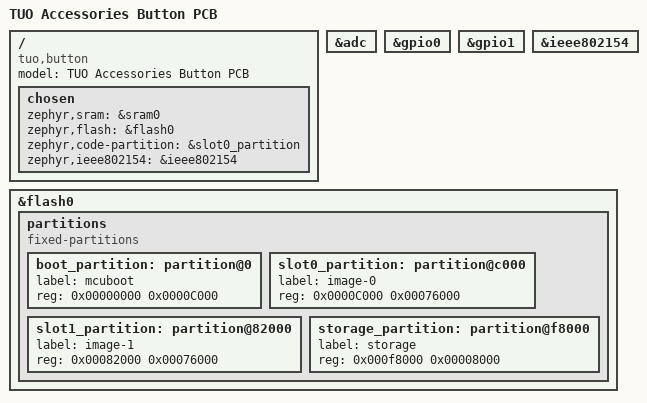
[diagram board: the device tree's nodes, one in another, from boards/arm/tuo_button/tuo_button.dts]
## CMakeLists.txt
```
cmake_minimum_required(VERSION 3.20.0)

find_package(Zephyr HINTS $ENV{ZEPHYR_BASE})

project(button)

include($ENV{MATTER_BASE}/config/nrfconnect/app/enable-gnu-std.cmake)
include($ENV{MATTER_BASE}/src/app/chip_data_model.cmake)

target_include_directories(app PRIVATE include matter)

target_sources(app PRIVATE
    src/main.cpp
    src/app_task.cpp
    src/button.cpp
    src/reset_switch.cpp
    src/battery.cpp
    matter/zap-generated/IMClusterCommandHandler.cpp
    matter/zap-generated/callback-stub.cpp
)

chip_configure_data_model(app
    INCLUDE_SERVER
    ZAP_FILE ${CMAKE_CURRENT_SOURCE_DIR}/matter/button.zap
)
```

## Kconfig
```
mainmenu "Button"

config BUTTON_GPIO
	int "Button GPIO"
	default 6

config RESET_SWITCH_GPIO
	int "Reset switch GPIO"
	default 24

source "${ZEPHYR_BASE}/../modules/lib/matter/config/nrfconnect/chip-module/Kconfig.features"
source "${ZEPHYR_BASE}/../modules/lib/matter/config/nrfconnect/chip-module/Kconfig.defaults"
source "Kconfig.zephyr"
```

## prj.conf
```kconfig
#
# Copyright (c) 2022 Nordic Semiconductor ASA
#
# SPDX-License-Identifier: LicenseRef-Nordic-5-Clause
#

# Version
CONFIG_CHIP_DEVICE_SOFTWARE_VERSION=1
CONFIG_CHIP_DEVICE_SOFTWARE_VERSION_STRING="0.1.0"

# CHIP
CONFIG_CHIP=y
CONFIG_CHIP_PROJECT_CONFIG="matter/chip_project_config.h"
CONFIG_CHIP_ENABLE_SLEEPY_END_DEVICE_SUPPORT=y
CONFIG_CHIP_THREAD_SSED=y
CONFIG_CHIP_ENABLE_PAIRING_AUTOSTART=y
CONFIG_CHIP_DEVICE_TYPE=15

# Thread
CONFIG_OPENTHREAD_MTD=y
CONFIG_OPENTHREAD_NORDIC_LIBRARY_MTD=y
CONFIG_OPENTHREAD_NRF_SECURITY_CHOICE=y

# Bluetooth
CONFIG_BT_DEVICE_NAME="Button"

# MCUboot
CONFIG_BOOTLOADER_MCUBOOT=n

# Other settings
CONFIG_STD_CPP14=y
CONFIG_THREAD_NAME=y
CONFIG_MPU_STACK_GUARD=y
CONFIG_RESET_ON_FATAL_ERROR=n
CONFIG_NET_IF_MCAST_IPV6_ADDR_COUNT=14
CONFIG_ADC=y

# RTT logging
CONFIG_STDOUT_CONSOLE=y
CONFIG_UART_CONSOLE=n
CONFIG_USE_SEGGER_RTT=y
CONFIG_SHELL_BACKEND_RTT=y
CONFIG_LOG_DEFAULT_LEVEL=4

#CONFIG_BUTTON_SINGLE_PRESS_TIME=100
#CONFIG_BUTTON_DOUBLE_PRESS_TIME=250
#CONFIG_BUTTON_LONG_PRESS_TIME=1000
```

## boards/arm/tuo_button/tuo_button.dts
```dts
/dts-v1/;
#include <nordic/nrf52840_qiaa.dtsi>

/ {
  model = "TUO Accessories Button PCB";
  compatible = "tuo,button";

  chosen {
    zephyr,sram = &sram0;
    zephyr,flash = &flash0;
    zephyr,code-partition = &slot0_partition;
    zephyr,ieee802154 = &ieee802154;
  };
};

&adc {
  status = "okay";
};

&gpio0 {
  status = "okay";
};

&gpio1 {
  status = "okay";
};

&ieee802154 {
  status = "okay";
};

&flash0 {
    partitions {
        compatible = "fixed-partitions";
        #address-cells = <1>;
        #size-cells = <1>;

        boot_partition: partition@0 {
          label = "mcuboot";
          reg = <0x00000000 0x0000C000>;
        };
        slot0_partition: partition@c000 {
          label = "image-0";
          reg = <0x0000C000 0x00076000>;
        };
        slot1_partition: partition@82000 {
          label = "image-1";
          reg = <0x00082000 0x00076000>;
        };
        storage_partition: partition@f8000 {
          label = "storage";
          reg = <0x000f8000 0x00008000>;
        };
    };
};
```

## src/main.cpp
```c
#include <zephyr/logging/log.h>
#include "app_task.hpp"

LOG_MODULE_REGISTER(app);

int main() {
	auto& task = AppTask::shared();

    auto err = task.init();

    if (err != 0) {
        LOG_ERR("Failed to initialize. Exiting...");
        return EXIT_FAILURE;
    }

    err = task.start();

    return err == 0 ? EXIT_SUCCESS : EXIT_FAILURE;
}
```

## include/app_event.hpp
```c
#pragma once

struct AppEvent;

typedef void (*event_callback_fn)(AppEvent event);

enum class AppEventType: unsigned char {
    None = 0,
    ButtonChanged
};

struct AppEvent {
    AppEventType type;
    event_callback_fn callback;

    union {
        struct {
            // Status returned from GPIO read
            // 0 = pressed, 1 = released, other values are errors
            int status;
        } button_changed;
    };
};
```

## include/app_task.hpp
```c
/*
 * Copyright (c) 2021 Nordic Semiconductor ASA
 *
 * SPDX-License-Identifier: LicenseRef-Nordic-5-Clause
 */

#pragma once

#include <platform/CHIPDeviceLayer.h>
#include "app_event.hpp"

class AppTask {
public:
	static AppTask& shared() {
		static AppTask app_task;
		return app_task;
	};

    bool initialized() const;
    int init();

    int start();

private:
    static void on_chip_event(const chip::DeviceLayer::ChipDeviceEvent* event, intptr_t arg);
    static void on_button_interrupt(int status);
    static void on_reset();

    static void on_button_change(AppEvent event);

    static void set_button(bool pressed);

    bool _initialized = false;
};
```

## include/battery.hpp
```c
#pragma once

namespace battery {

    // Initializes the battery management system
    int init();

    // Gets the current battery percentage
    // Positive values indicate half battery percentages (200 = 100%, 100 = 50%, etc..), negative values an error
    int get_percentage();

}
```

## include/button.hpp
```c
#pragma once

#include "zephyr/drivers/gpio.h"

typedef void (*button_interrupt_fn)(int status);

namespace button {
    // Initializes the button
    int init();

    // Read a value from the button
    // Returns an integer indicating the status of the GPIO read
    // 0 = pressed, 1 = released, other values are errors
    int read();

    // Enables the button interrupt with the specified callback
    // Can only be run once
    int enable_interrupt(button_interrupt_fn interrupt_handler);
}
```

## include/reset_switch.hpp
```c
#pragma once

#include "zephyr/drivers/gpio.h"

typedef void (*reset_fn)();

namespace reset_switch {
    // Initializes the reset switch
    int init();

    // Read a value from the reset switch
    // Returns an integer indicating the status of the GPIO read
    // 0 = pressed, 1 = not pressed, other values are errors
    int read();

    // Enables the reset switch interrupt with the specified callback
    // Can only be run once
    int enable_interrupt(reset_fn reset_handler);
}
```

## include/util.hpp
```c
#pragma once

#define CHECK_STATUS(info, status, condition) if ((status) condition) { LOG_ERR("Invalid status while " info ": %d", status); return status; }
#define CHECK_SUCCESS(info, status) CHECK_STATUS(info, status, != 0)

#define CHECK_STATUS_VOID(info, status, condition) if ((status) condition) { LOG_ERR("Invalid status while " info ": %d", status); return; }
#define CHECK_SUCCESS_VOID(info, status) CHECK_STATUS_VOID(info, status, != 0)

#define CHECK_CHIP_STATUS(info, status, condition) if ((status) condition) { LOG_ERR("Invalid status while " info ": %s (%d)", status.AsString(), status.AsInteger()); return status.AsInteger(); }
#define CHECK_CHIP_SUCCESS(info, status) CHECK_CHIP_STATUS(info, status, != CHIP_NO_ERROR)
```

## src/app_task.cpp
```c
#include "app_task.hpp"


#include <app/server/OnboardingCodesUtil.h>
#include <app/server/Server.h>
#include <app/clusters/switch-server/switch-server.h>
#include <app-common/zap-generated/attribute-id.h>
#include <app-common/zap-generated/attribute-type.h>
#include <app-common/zap-generated/attributes/Accessors.h>
#include <app-common/zap-generated/cluster-id.h>
#include <platform/CHIPDeviceLayer.h>
#include <platform/ThreadStackManager.h>
#include <credentials/DeviceAttestationCredsProvider.h>
#include <credentials/examples/DeviceAttestationCredsExample.h>

#include "app_event.hpp"
#include "button.hpp"
#include "reset_switch.hpp"
#include "battery.hpp"
#include "util.hpp"

LOG_MODULE_DECLARE(app);

using namespace ::chip::Credentials;
using namespace ::chip::DeviceLayer;

constexpr chip::EndpointId button_endpoint = 1;

K_MSGQ_DEFINE(app_event_queue, sizeof(AppEvent), 10, alignof(AppEvent));

int AppTask::init() {
    LOG_INF("Initializing...");

    // Hardware initialization
    int err = button::init();
    CHECK_SUCCESS("initializing button", err)

    err = reset_switch::init();
    CHECK_SUCCESS("initializing reset switch", err)

    err = battery::init();
    CHECK_SUCCESS("initializing battery management", err)

    // Matter initialization
    CHIP_ERROR chip_err = chip::Platform::MemoryInit();
    CHECK_CHIP_SUCCESS("initializing memory", chip_err)

    chip_err = PlatformMgr().InitChipStack();
    CHECK_CHIP_SUCCESS("initializing Matter stack", chip_err)

    chip_err = ThreadStackMgr().InitThreadStack();
    CHECK_CHIP_SUCCESS("initializing Thread stack", chip_err)

    chip_err = ConnectivityMgr().SetThreadDeviceType(ConnectivityManager::kThreadDeviceType_SynchronizedSleepyEndDevice);
    CHECK_CHIP_SUCCESS("setting Thread device type", chip_err)

    // TODO: Proper credentials
    SetDeviceAttestationCredentialsProvider(Examples::GetExampleDACProvider());

    // TODO: Proper parameter storage
    static chip::CommonCaseDeviceServerInitParams init_params;
    init_params.InitializeStaticResourcesBeforeServerInit();

    chip_err = chip::Server::GetInstance().Init(init_params);
    CHECK_CHIP_SUCCESS("initializing server", chip_err)

    ConfigurationMgr().LogDeviceConfig();
    PrintOnboardingCodes(chip::RendezvousInformationFlag::kBLE);

    chip_err = PlatformMgr().AddEventHandler(on_chip_event, 0);
    CHECK_CHIP_SUCCESS("adding CHIP event handler", chip_err)

    chip_err = PlatformMgr().StartEventLoopTask();
    CHECK_CHIP_SUCCESS("starting event loop task", chip_err)

    _initialized = true;
    return 0;
}

int AppTask::start() {
    if (!_initialized) {
        LOG_ERR("Application is not initialized");
        return 1;
    }

    int status = button::enable_interrupt(on_button_interrupt);
    CHECK_SUCCESS("enabling button interrupt", status)

    status = button::read();

    if (status != 0 && status != 1) {
        LOG_ERR("Invalid button status on initial read: %i", status);
    } else {
        set_button(status == 0);
    }

    status = reset_switch::enable_interrupt(on_reset);
    CHECK_SUCCESS("enabling reset switch interrupt", status)

    auto percentage = battery::get_percentage();
    CHECK_STATUS("getting battery percentage", percentage, < 0);
    LOG_INF("Current battery percentage: %d%%", percentage / 2);

    AppEvent event {};

    while (true) {
        status = k_msgq_get(&app_event_queue, &event, K_FOREVER);

        if (status != 0) {
            LOG_WRN("App event queue returned invalid status: %i", status);
            continue;
        }

        if (event.callback) {
            event.callback(event);
        } else {
            LOG_WRN("App event does not have a callback");
        }
    }
}

void AppTask::on_chip_event(const chip::DeviceLayer::ChipDeviceEvent* event, intptr_t /* arg */) {
    LOG_INF("CHIP event: %u", event->Type);
}

void AppTask::on_button_interrupt(int status) {
    LOG_INF("Button status: %d", status);
    AppEvent event {
        .type = AppEventType::ButtonChanged,
        .callback = on_button_change,
        .button_changed = {
            .status = status
        }
    };

    auto _status = k_msgq_put(&app_event_queue, &event, K_NO_WAIT);

    if (_status != 0) {
        LOG_ERR("Failed to post ButtonChanged event: %i", _status);
    }
}

void AppTask::on_reset() {
    LOG_INF("Performing factory reset");
    chip::Server::GetInstance().ScheduleFactoryReset();
}

void AppTask::on_button_change(AppEvent event) {
    if (event.type != AppEventType::ButtonChanged) return;

    auto status = event.button_changed.status;

    if (status != 0 && status != 1) {
        LOG_ERR("Invalid status in ButtonChanged event: %i", status);
        return;
    }

    set_button(status == 0);
}

void AppTask::set_button(bool pressed) {
    SystemLayer().ScheduleLambda([pressed] {
        auto status = chip::app::Clusters::Switch::Attributes::CurrentPosition::Set(button_endpoint, pressed);

        if (pressed) {
            chip::app::Clusters::SwitchServer::Instance().OnInitialPress(button_endpoint, 1);
        } else {
            chip::app::Clusters::SwitchServer::Instance().OnShortRelease(button_endpoint, 1);
        }

        if (status != EMBER_ZCL_STATUS_SUCCESS) {
            LOG_ERR("Failed to update button cluster: %i", status);
        }
    });
}

bool AppTask::initialized() const { return _initialized; }
```

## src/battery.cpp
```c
#include "battery.hpp"

#include <zephyr/drivers/adc.h>
#include <zephyr/logging/log.h>
#include "util.hpp"

LOG_MODULE_DECLARE(app);

namespace battery {

    namespace {
        const struct device* _device = DEVICE_DT_GET(DT_NODELABEL(adc));

        const struct adc_channel_cfg _adc_config {
            .gain = ADC_GAIN_1_6,
            .reference = ADC_REF_INTERNAL,
            .acquisition_time = ADC_ACQ_TIME(ADC_ACQ_TIME_MICROSECONDS, 40),
            .channel_id = 0,
            .differential = 0,
            .input_positive = SAADC_CH_PSELP_PSELP_VDD
        };
    }

    int init() {
        LOG_DBG("Initializing battery management");

        int status = adc_channel_setup(_device, &_adc_config);

        CHECK_SUCCESS("initializing battery ADC", status)

        return status;
    }

    int get_percentage() {
        int sample = 0;

        struct adc_sequence sequence {
            .channels = BIT(0),
            .buffer = &sample,
            .buffer_size = sizeof(sample),
            .resolution = 14,
            .oversampling = 4,
            .calibrate = true
        };

        int status = adc_read(_device, &sequence);
        CHECK_SUCCESS("measuring battery ADC", status);

        auto ref = adc_ref_internal(_device);

        LOG_DBG("Battery raw: %u, reference: %u", sample, ref);

        adc_raw_to_millivolts(ref, _adc_config.gain, sequence.resolution, &sample);

        LOG_DBG("Battery mV: %d", sample);

        // Clip from 2V to 3V
        sample = sample <= 3000 ? (sample >= 2000 ? sample : 2000) : 3000;

        // Discharge curve for CR2430 shows near linear line to 2.5V for the first 80%, dropping faster to 2V for the last 20%
        // This results in the following equations:
        // Above 2500, percentage = sample * 80/500 - 380
        // Below 2500, percentage = sample * 20/500 - 80

        return sample >= 2500 ? sample * 80 / 500 - 380 : sample * 20/500 - 80;
    }

}
```

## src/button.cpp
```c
#include "button.hpp"

#include <zephyr/drivers/gpio.h>
#include <zephyr/logging/log.h>
#include <zephyr/kernel.h>
#include "util.hpp"


LOG_MODULE_DECLARE(app);

namespace button {

    namespace {
        const struct device* _device = DEVICE_DT_GET(DT_NODELABEL(gpio0));

        struct gpio_callback _callback;
        button_interrupt_fn _interrupt_handler;

        // State machine
        enum button_state_t {
            BUTTON_RELEASED,
            BUTTON_WAIT_DOUBLE_PRESS_OR_LONG_PRESS,
            BUTTON_WAIT_LONG_PRESS
        };

        enum button_event_t{
            BUTTON_SINGLE_PRESSED,
            BUTTON_DOUBLE_PRESSED,
            BUTTON_LONG_PRESSED
        };

        button_state_t _button_state = BUTTON_RELEASED;

         // Timers
        K_TIMER_DEFINE(_double_press_timer, nullptr, nullptr);
        K_TIMER_DEFINE(_long_press_timer, nullptr, nullptr);

        // Timer callback functions
        void double_press_timer_callback(k_timer* timer_id) {
            LOG_INF("Double press timer expired");
            _button_state = BUTTON_RELEASED;
            _interrupt_handler(BUTTON_SINGLE_PRESSED);
        }

        void long_press_timer_callback(k_timer* timer_id) {
            LOG_INF("Long press timer expired");
            _button_state = BUTTON_RELEASED;
            _interrupt_handler(BUTTON_LONG_PRESSED);
        }

        // Timestamp of the last button press
        uint32_t _last_button_press_time = 0;

        // Number of button presses
        int _num_button_presses = 0;

        /*void gpio_handler(const struct device* port, struct gpio_callback* callback, gpio_port_pins_t pins) {
            LOG_INF("*****************************\n");
            LOG_INF("*****************************\n");
            LOG_INF("\n\n");
            
            // This call should not be delayed
            int value = read();
            _interrupt_handler(value);
        }

        void gpio_handler(const struct device* port, struct gpio_callback* callback, gpio_port_pins_t pins) {
            int value = read();
            uint32_t current_time = k_uptime_get_32();

            if (value == 0) {
                // Button is pressed
                if (_button_state == BUTTON_RELEASED) {
                    // Button was just pressed
                    _button_state = BUTTON_PRESSED;
                    _last_button_press_time = current_time;
                    //LOG_INF("Button pressed");
                } else if (_button_state == BUTTON_PRESSED) {
                    // Button was already pressed
                    if (current_time - _last_button_press_time >= 1000) {
                        // Button has been held down for more than 1 second, trigger long press
                        _button_state = BUTTON_LONG_PRESSED;
                        _interrupt_handler(BUTTON_LONG_PRESSED);
                        LOG_INF("Button long press");
                    }
                } else if (_button_state == BUTTON_LONG_PRESSED) {
                    // Button was already long pressed
                    // Do nothing
                } else if (_button_state == BUTTON_DOUBLE_PRESSED) {
                    // Button was already double pressed
                    // Do nothing
                }
            } else {
                // Button is released
                if (_button_state == BUTTON_PRESSED) {
                    // Button was just released
                    if (current_time - _last_button_press_time >= 250) {
                        // Button was released after less than 250ms, trigger double press
                        _num_button_presses += 1;
                        if (_num_button_presses == 2) {
                            _button_state = BUTTON_DOUBLE_PRESSED;
                            _interrupt_handler(BUTTON_DOUBLE_PRESSED);
                            _num_button_presses = 0;
                            LOG_INF("Button double press");
                        } else {
                            // Wait for another button press
                            _last_button_press_time = current_time;
                        }
                    } else {
                        // Button was released after more than 250ms, trigger single press
                        _button_state = BUTTON_RELEASED;
                        _interrupt_handler(BUTTON_RELEASED);
                        LOG_INF("Button single press");
                    }
                } else if (_button_state == BUTTON_LONG_PRESSED) {
                    // Button was just released after a long press
                    _button_state = BUTTON_RELEASED;
                    _interrupt_handler(BUTTON_RELEASED);
                    //LOG_INF("Button long press released");
                } else if (_button_state == BUTTON_DOUBLE_PRESSED) {
                    // Button was just released after a double press
                    _button_state = BUTTON_RELEASED;
                    _interrupt_handler(BUTTON_RELEASED);
                    //LOG_INF("Button double press released");
                }
            }
        }*/
/*
        // GPIO interrupt handler
        void gpio_handler(const struct device* port, struct gpio_callback* callback, gpio_port_pins_t pins) {
            if (pins & BIT(CONFIG_BUTTON_GPIO)) {
                int value = read();
                switch (_button_state) {
                    case BUTTON_RELEASED:
                        if (value == 0) {
                            _button_state = BUTTON_WAIT_PRESS;
                            k_timer_start(&_single_press_timer, K_MSEC(CONFIG_BUTTON_SINGLE_PRESS_TIME), K_NO_WAIT);
                            LOG_INF("Button pressed, waiting for release or double press");
                        }
                        break;
                    case BUTTON_WAIT_PRESS:
                        if (value == 1) {
                            k_timer_stop(&_single_press_timer);
                            _button_state = BUTTON_RELEASED;
                            _interrupt_handler(BUTTON_SINGLE_PRESSED);
                            LOG_INF("Button single pressed");
                        } else if (k_timer_status_get(&_single_press_timer) > 0) {
                            _button_state = BUTTON_WAIT_DOUBLE_PRESS;
                            k_timer_start(&_double_press_timer, K_MSEC(CONFIG_BUTTON_DOUBLE_PRESS_TIME), K_NO_WAIT);
                            LOG_INF("Button pressed again, waiting for release or triple press");
                        }
                        break;
                    case BUTTON_WAIT_DOUBLE_PRESS:
                        if (value == 1) {
                            k_timer_stop(&_double_press_timer);
                            _button_state = BUTTON_RELEASED;
                            _interrupt_handler(BUTTON_DOUBLE_PRESSED);
                            LOG_INF("Button double pressed");
                        } else if (k_timer_status_get(&_double_press_timer) > 0) {
                            _button_state = BUTTON_WAIT_LONG_PRESS;
                            k_timer_start(&_long_press_timer, K_MSEC(CONFIG_BUTTON_LONG_PRESS_TIME), K_NO_WAIT);
                            LOG_INF("Button pressed again, waiting for long press");
                        }
                        break;
                    case BUTTON_WAIT_LONG_PRESS:
                        if (value == 1) {
                            k_timer_stop(&_long_press_timer);
                            _button_state = BUTTON_RELEASED;
                            _interrupt_handler(BUTTON_LONG_PRESSED);
                            LOG_INF("Button long pressed");
                        }
                        break;
                }
            }
        }
*/

         // GPIO interrupt handler
        void gpio_handler(const struct device* port, struct gpio_callback* callback, gpio_port_pins_t pins) {
            int value = read();
            if (value == 0) {
                if (_button_state == BUTTON_RELEASED) {
                    _button_state = BUTTON_WAIT_DOUBLE_PRESS_OR_LONG_PRESS;
                    //k_timer_start(&_double_press_timer, K_MSEC(CONFIG_BUTTON_DOUBLE_PRESS_TIME), K_NO_WAIT);
                    k_timer_start(&_double_press_timer, K_MSEC(250), K_NO_WAIT);
                    LOG_INF("*********Button pressed, waiting for double press or long press");
                } else if (_button_state == BUTTON_WAIT_DOUBLE_PRESS_OR_LONG_PRESS) {
                    _button_state = BUTTON_WAIT_LONG_PRESS;
                    k_timer_stop(&_double_press_timer);
                    //k_timer_start(&_long_press_timer, K_MSEC(CONFIG_BUTTON_LONG_PRESS_TIME), K_NO_WAIT);
                    k_timer_start(&_long_press_timer, K_MSEC(1000), K_NO_WAIT);
                    LOG_INF("*********Button pressed twice, waiting for long press");
                }
            } else {
                if (_button_state == BUTTON_WAIT_LONG_PRESS) {
                    k_timer_stop(&_long_press_timer);
                    _button_state = BUTTON_RELEASED;
                    _interrupt_handler(BUTTON_LONG_PRESSED);
                    LOG_INF("*********Button long pressed");
                } else if (_button_state == BUTTON_WAIT_DOUBLE_PRESS_OR_LONG_PRESS) {
                    k_timer_stop(&_double_press_timer);
                    _button_state = BUTTON_RELEASED;
                    _interrupt_handler(BUTTON_SINGLE_PRESSED);
                    LOG_INF("*********Button single pressed");
                }
            }
        }






    }

    int init() {
        //LOG_DBG("Initializing button GPIO: %i", CONFIG_BUTTON_GPIO);
        LOG_INF("Initializing button GPIO: %i", CONFIG_BUTTON_GPIO);

        int status = gpio_pin_configure(_device, CONFIG_BUTTON_GPIO, GPIO_INPUT);// | GPIO_PULL_UP);

        CHECK_SUCCESS("initializing button GPIO", status)

        return status;
    }

    int read() {
        //LOG_DBG("Reading button GPIO: %i", CONFIG_BUTTON_GPIO);
        //LOG_INF("Reading button GPIO: %i", CONFIG_BUTTON_GPIO);

        int status = gpio_pin_get(_device, CONFIG_BUTTON_GPIO);

        //CHECK_STATUS("reading button GPIO", status, < 0)

        return status;
    }

    int enable_interrupt(button_interrupt_fn interrupt_handler) {
        //LOG_DBG("Enabling button interrupt");
        LOG_INF("Enabling button interrupt");

        if (!interrupt_handler) {
            LOG_ERR("Invalid parameter for button enable interrupt: interrupt_handler is null");
            return 1;
        }

        if (_interrupt_handler) {
            LOG_ERR("Button interrupt already configured");
            return 1;
        }

        _interrupt_handler = interrupt_handler;

        int status = gpio_pin_interrupt_configure(_device, CONFIG_BUTTON_GPIO, GPIO_INT_EDGE_BOTH);

        CHECK_SUCCESS("configuring button GPIO interrupt", status)

        gpio_init_callback(&_callback, gpio_handler, BIT(CONFIG_BUTTON_GPIO));
        status = gpio_add_callback(_device, &_callback);

        CHECK_SUCCESS("adding button GPIO callback", status)

         // Start the timers
        k_timer_init(&_double_press_timer, double_press_timer_callback, nullptr);
        k_timer_init(&_long_press_timer, long_press_timer_callback, nullptr);

        return status;
    }
}
```

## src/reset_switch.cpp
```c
#include "reset_switch.hpp"

#include <zephyr/drivers/gpio.h>
#include <zephyr/logging/log.h>
#include <zephyr/kernel.h>
#include "util.hpp"

LOG_MODULE_DECLARE(app);

namespace reset_switch {

    namespace {
        const struct device* _device = DEVICE_DT_GET(DT_NODELABEL(gpio0));

        struct gpio_callback _callback;
        reset_fn _reset_handler;

        // Timer work handler
        // Called from the system work queue, calling the reset handler
        void work_handler(struct k_work* work) {
            _reset_handler();
        }

        K_WORK_DEFINE(_work, work_handler);

        // Timer handler for reset switch
        // Dispatches a work item to the system work queue, so the reset handler is not running in the ISR
        void timer_handler(struct k_timer* timer) {
            k_work_submit(&_work);
            k_timer_stop(timer);
        }

        K_TIMER_DEFINE(_timer, timer_handler, nullptr);

        // Interrupt handler for reset switch
        // When the switch is pressed, it starts the timer for 5 seconds
        // When the switch is released, it stops the timer
        void gpio_handler(const struct device* port, struct gpio_callback* callback, gpio_port_pins_t pins) {
            // This call should not be delayed
            int value = read();

            if (value == 0) {
                k_timer_start(&_timer, K_SECONDS(5), K_FOREVER);
            } else if (value == 1) {
                k_timer_stop(&_timer);
            }
        }

    }

    int init() {
        LOG_DBG("Initializing reset switch GPIO: %i", CONFIG_RESET_SWITCH_GPIO);

        int status = gpio_pin_configure(_device, CONFIG_RESET_SWITCH_GPIO, GPIO_INPUT);

        CHECK_SUCCESS("initializing reset switch GPIO", status)

        return status;
    }

    int read() {
        LOG_DBG("Reading reset switch GPIO: %i", CONFIG_RESET_SWITCH_GPIO);

        int status = gpio_pin_get(_device, CONFIG_RESET_SWITCH_GPIO);

        CHECK_STATUS("reading reset switch GPIO", status, < 0)

        return status;
    }

    int enable_interrupt(reset_fn reset_handler) {
        LOG_DBG("Enabling reset switch interrupt");

        if (!reset_handler) {
            LOG_ERR("Invalid parameter for reset switch enable interrupt: interrupt_handler is null");
            return 1;
        }

        if (_reset_handler) {
            LOG_ERR("Reset switch interrupt already configured");
            return 1;
        }

        _reset_handler = reset_handler;

        int status = gpio_pin_interrupt_configure(_device, CONFIG_RESET_SWITCH_GPIO, GPIO_INT_EDGE_BOTH);

        CHECK_SUCCESS("configuring reset switch GPIO interrupt", status)

        gpio_init_callback(&_callback, gpio_handler, BIT(CONFIG_RESET_SWITCH_GPIO));
        status = gpio_add_callback(_device, &_callback);

        CHECK_SUCCESS("adding reset switch GPIO callback", status)

        return status;
    }

}
```
